# PCIE0_DAT register map
Vendor: Texas Instruments
Peripheral module from a debugger description file (folder am65x).
Registers are 32-bit, read-write, reset 0x0 unless marked. A register's access mark holds for its fields unless they carry their own. Offsets are as the file gives them; lines under a group give offsets from that group; [hi:lo] are bit positions; {n}, {i} and the like mark numbered series; 'fields as' and 'values as' point back to an identical list; <NAME> marks a mode.

## PCIE0_DAT (part 1 of 6)
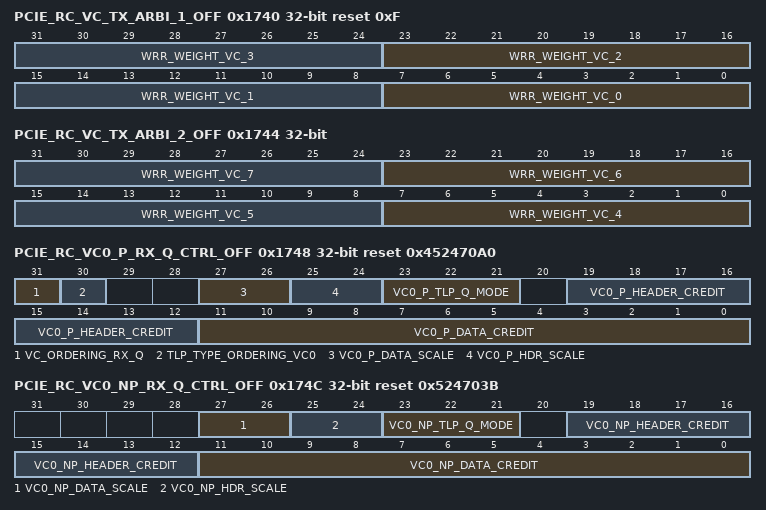
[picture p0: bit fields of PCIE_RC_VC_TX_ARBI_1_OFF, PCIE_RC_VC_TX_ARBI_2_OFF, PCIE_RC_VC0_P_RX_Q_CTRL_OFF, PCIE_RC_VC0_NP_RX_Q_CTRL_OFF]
0x1740 PCIE_RC_VC_TX_ARBI_1_OFF ro reset 0xF — VC Transmit Arbitration Register 1
  [8n+7:8n] WRR_WEIGHT_VC_{n} (n=0..3) — WRR Weight for VC{n} Note: The access attributes of this field are as follows: - Dbi: R
0x1744 PCIE_RC_VC_TX_ARBI_2_OFF ro — VC Transmit Arbitration Register 2
  [8n-25:8n-32] WRR_WEIGHT_VC_{n} (n=4..7) — WRR Weight for VC{n} Note: The access attributes of this field are as follows: - Dbi: R
0x1748 PCIE_RC_VC0_P_RX_Q_CTRL_OFF access per field reset 0x452470A0 — Segmented-Buffer VC0 Posted Receive Queue Control.
  [31] VC_ORDERING_RX_Q rw — VC Ordering for Receive Queues Determines the VC ordering rule for the receive queues, used only in the segmented-buffer configuration: - 1: Strict ordering, higher numbered VCs have higher priority - 0: Round robin Note: This register field is sticky
  [30] TLP_TYPE_ORDERING_VC0 rw — TLP Type Ordering for VC0 Determines the TLP type ordering rule for VC0 receive queues, used only in the segmented-buffer configuration: - 1: PCIe ordering rules [recommended] - 0: Strict ordering: posted, completion, then non-posted Note: This register field is sticky
  [27:26] VC0_P_DATA_SCALE rw — VC0 Scale Posted Data Credites Note: This register field is sticky
  [25:24] VC0_P_HDR_SCALE rw — VC0 Scale Posted Header Credites Note: This register field is sticky
  [23:21] VC0_P_TLP_Q_MODE rw — Reserved Note: This register field is sticky
  [19:12] VC0_P_HEADER_CREDIT ro — VC0 Posted Header Credits The number of initial posted header credits for VC0, used only in the segmented-buffer configuration Note: The access attributes of this field are as follows: - Dbi: R [sticky] Note: This register field is sticky
  [11:0] VC0_P_DATA_CREDIT ro — VC0 Posted Data Credits The number of initial posted data credits for VC0, used only in the segmented-buffer configuration Note: The access attributes of this field are as follows: - Dbi: R [sticky] Note: This register field is sticky
0x174C PCIE_RC_VC0_NP_RX_Q_CTRL_OFF access per field reset 0x524703B — Segmented-Buffer VC0 Non-Posted Receive Queue Control.
  [27:26] VC0_NP_DATA_SCALE rw — VC0 Scale Non-Posted Data Credites Note: This register field is sticky
  [25:24] VC0_NP_HDR_SCALE rw — VC0 Scale Non-Posted Header Credites Note: This register field is sticky
  [23:21] VC0_NP_TLP_Q_MODE rw — Reserved Note: This register field is sticky
  [19:12] VC0_NP_HEADER_CREDIT ro — VC0 Non-Posted Header Credits The number of initial non-posted header credits for VC0, used only in the segmented-buffer configuration Note: The access attributes of this field are as follows: - Dbi: R [sticky] Note: This register field is sticky
  [11:0] VC0_NP_DATA_CREDIT ro — VC0 Non-Posted Data Credits The number of initial non-posted data credits for VC0, used only in the segmented-buffer configuration Note: The access attributes of this field are as follows: - Dbi: R [sticky] Note: This register field is sticky
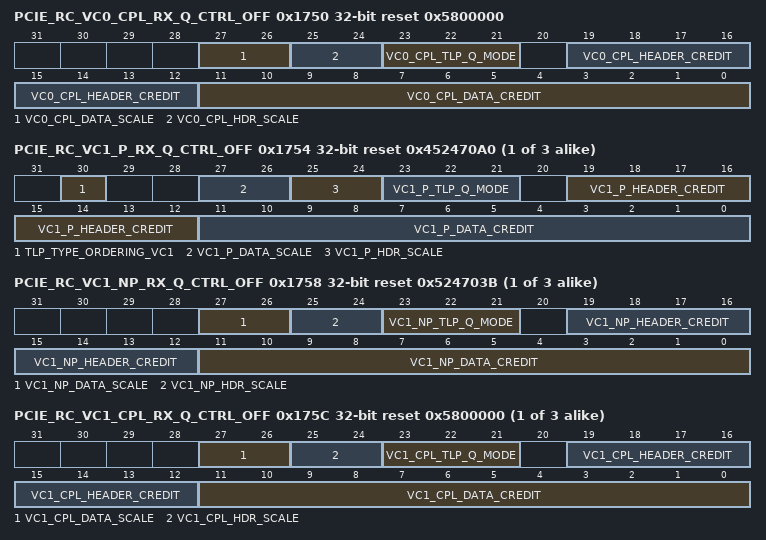
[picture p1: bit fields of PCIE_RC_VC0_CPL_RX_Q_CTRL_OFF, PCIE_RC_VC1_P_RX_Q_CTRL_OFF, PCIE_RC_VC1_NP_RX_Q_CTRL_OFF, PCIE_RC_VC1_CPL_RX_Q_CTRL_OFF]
0x1750 PCIE_RC_VC0_CPL_RX_Q_CTRL_OFF access per field reset 0x5800000 — Segmented-Buffer VC0 Completion Receive Queue Control.
  [27:26] VC0_CPL_DATA_SCALE rw — VC0 Scale CPL Data Credites Note: This register field is sticky
  [25:24] VC0_CPL_HDR_SCALE rw — VC0 Scale CPL Header Credites Note: This register field is sticky
  [23:21] VC0_CPL_TLP_Q_MODE rw — Reserved Note: This register field is sticky
  [19:12] VC0_CPL_HEADER_CREDIT ro — VC0 Completion Header Credits The number of initial Completion header credits for VC0, used only in the segmented-buffer configuration Note: The access attributes of this field are as follows: - Dbi: R [sticky] Note: This register field is sticky
  [11:0] VC0_CPL_DATA_CREDIT ro — VC0 Completion Data Credits The number of initial Completion data credits for VC0, used only in the segmented-buffer configuration Note: The access attributes of this field are as follows: - Dbi: R [sticky] Note: This register field is sticky
{0x1748+0xC*i} PCIE_RC_VC{i}_P_RX_Q_CTRL_OFF access per field reset 0x452470A0 (i=1..3) — Segmented-Buffer VC#i Posted Receive Queue Control.
  [30] TLP_TYPE_ORDERING_VC{i} rw — TLP Type Ordering for VC#i Determines the TLP type ordering rule for VC#i receive queues, used only in the segmented-buffer configuration: - 1: PCIe ordering rules [recommended] - 0: Strict ordering: posted, completion, then non-posted Note: This register field is sticky
  [27:26] VC{i}_P_DATA_SCALE rw — VC{i} Scale Posted Data Credites Note: This register field is sticky
  [25:24] VC{i}_P_HDR_SCALE rw — VC{i} Scale Posted Header Credites Note: This register field is sticky
  [23:21] VC{i}_P_TLP_Q_MODE rw — Reserved Note: This register field is sticky
  [19:12] VC{i}_P_HEADER_CREDIT ro — VC{i} Posted Header Credits The number of initial posted header credits for VC#i, used only in the segmented-buffer configuration Note: The access attributes of this field are as follows: - Dbi: R [sticky] Note: This register field is sticky
  [11:0] VC{i}_P_DATA_CREDIT ro — VC{i} Posted Data Credits The number of initial posted data credits for VC#i, used only in the segmented-buffer configuration Note: The access attributes of this field are as follows: - Dbi: R [sticky] Note: This register field is sticky
{0x174C+0xC*i} PCIE_RC_VC{i}_NP_RX_Q_CTRL_OFF access per field reset 0x524703B (i=1..3) — Segmented-Buffer VC#i Non-Posted Receive Queue Control.
  [27:26] VC{i}_NP_DATA_SCALE rw — VC{i} Scale Non-Posted Data Credites Note: This register field is sticky
  [25:24] VC{i}_NP_HDR_SCALE rw — VC{i} Scale Non-Posted Header Credites Note: This register field is sticky
  [23:21] VC{i}_NP_TLP_Q_MODE rw — Reserved Note: This register field is sticky
  [19:12] VC{i}_NP_HEADER_CREDIT ro — VC#i Non-Posted Header Credits The number of initial non-posted header credits for VC#i, used only in the segmented-buffer configuration Note: The access attributes of this field are as follows: - Dbi: R [sticky] Note: This register field is sticky
  [11:0] VC{i}_NP_DATA_CREDIT ro — VC#i Non-Posted Data Credits The number of initial non-posted data credits for VC#i, used only in the segmented-buffer configuration Note: The access attributes of this field are as follows: - Dbi: R [sticky] Note: This register field is sticky
{0x1750+0xC*i} PCIE_RC_VC{i}_CPL_RX_Q_CTRL_OFF access per field reset 0x5800000 (i=1..3) — Segmented-Buffer VC#i Completion Receive Queue Control.
  [27:26] VC{i}_CPL_DATA_SCALE rw — VC{i} Scale CPL Data Credites Note: This register field is sticky
  [25:24] VC{i}_CPL_HDR_SCALE rw — VC{i} Scale CPL Header Credites Note: This register field is sticky
  [23:21] VC{i}_CPL_TLP_Q_MODE rw — Reserved Note: This register field is sticky
  [19:12] VC{i}_CPL_HEADER_CREDIT ro — VC#i Completion Header Credits The number of initial Completion header credits for VC#i, used only in the segmented-buffer configuration Note: The access attributes of this field are as follows: - Dbi: R [sticky] Note: This register field is sticky
  [11:0] VC{i}_CPL_DATA_CREDIT ro — VC#i Completion Data Credits The number of initial Completion data credits for VC#i, used only in the segmented-buffer configuration Note: The access attributes of this field are as follows: - Dbi: R [sticky] Note: This register field is sticky
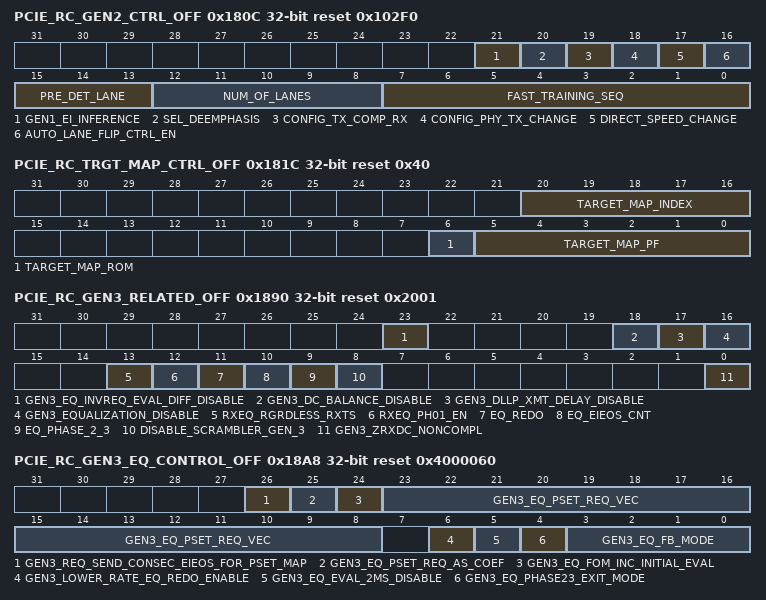
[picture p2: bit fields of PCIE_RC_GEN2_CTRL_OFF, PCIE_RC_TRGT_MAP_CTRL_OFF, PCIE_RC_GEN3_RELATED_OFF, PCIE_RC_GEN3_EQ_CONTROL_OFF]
0x180C PCIE_RC_GEN2_CTRL_OFF access per field reset 0x102F0 — Link Width and Speed Change Control Register.
  [21] GEN1_EI_INFERENCE rw — Electrical Idle Inference Mode at Gen1 Rate Programmable mode to determine inferred electrical idle [EI] in RecoverySpeed or LoopbackActive [as slave] state at Gen1 speed by looking for a '1' value on RxElecIdle instead of looking for a '0' on RxValid If the PHY fails to deassert the RxValid signal in RecoverySpeed or LoopbackActive [because of corrupted EIOS for example], then EI cannot be inferred successfully in the controller by just detecting the condition RxValid= 0 - 0: Use RxElecIdle signal to infer Electrical Idle - 1: Use RxValid signal to infer Electrical Idle Note: This register field is sticky
  [20] SEL_DEEMPHASIS rw — Used to set the de-emphasis level for upstream ports This bit selects the level of de-emphasis the link operates at - 0: -6 dB - 1: -35 dB This field is reserved [fixed to '0'] for M-PCIe Note: The access attributes of this field are as follows: - Dbi: R/W [sticky] Note: This register field is sticky
  [19] CONFIG_TX_COMP_RX rw — Config Tx Compliance Receive Bit When set to 1, signals LTSSM to transmit TS ordered sets with the compliance receive bit assert [equal to '1'] This field is reserved [fixed to '0'] for M-PCIe Note: The access attributes of this field are as follows: - Dbi: R/W [sticky] Note: This register field is sticky
  [18] CONFIG_PHY_TX_CHANGE rw — Config PHY Tx Swing Controls the PHY transmitter voltage swing level The controller drives the mac_phy_txswing output from this register bit field - 0: Full Swing - 1: Low Swing This field is reserved [fixed to '0'] for M-PCIe Note: The access attributes of this field are as follows: - Dbi: R/W [sticky] Note: This register field is sticky
  [17] DIRECT_SPEED_CHANGE rw — Directed Speed Change Writing '1' to this field instructs the LTSSM to initiate a speed change to Gen2 or Gen3 after the link is initialized at Gen1 speed When the speed change occurs, the controller will clear the contents of this field and a read to this field by your software will return a '0' To manually initiate the speed change: - Write to PCIE_RC_LINK_CONTROL2_LINK_STATUS2_REG PCIE_CAP_TARGET_LINK_SPEED in the local device - Deassert this field - Assert this field If you set the default of this field using the DEFAULT_GEN2_SPEED_CHANGE configuration parameter to '1', then the speed change is initiated automatically after link up, and the controller clears the contents of this field If you want to prevent this automatic speed change, then write a lower speed value to the Target Link Speed field of the Link Control 2 register [LINK_CONTROL2_LINK_STATUS2_OFF PCIE_CAP_TARGET_LINK_SPEED] through the DBI before link up This field is reserved [fixed to '0'] for M-PCIe Note: The access attributes of this field are as follows: - Dbi: R/W
  [16] AUTO_LANE_FLIP_CTRL_EN rw — Enable Auto flipping of the lanes You must set the CX_AUTO_LANE_FLIP_CTRL_EN configuration parameter to include the hardware for this feature in the controller This field is reserved [fixed to '0'] for M-PCIe Note: The access attributes of this field are as follows: - Dbi: R/W [sticky] Note: This register field is sticky
  [15:13] PRE_DET_LANE rw — Predetermined Lane for Auto Flip This field defines which physical lane is connected to logical Lane0 by the flip operation performed in Detect Allowed values are: - 3'b 000: Connect logical Lane0 to physical lane 0 or CX_NL-1 or CX_NL/ 2-1 or CX_NL/ 4-1 or CX_NL/ 8-1, depending on which lane is detected - 3'b 001: Connect logical Lane0 to physical lane 1 - 3'b 010: Connect logical Lane0 to physical lane 3 - 3'b 011: Connect logical Lane0 to physical lane 7 - 3'b 100: Connect logical Lane0 to physical lane 15 This field is used to restrict the receiver detect procedure to a particular lane when the default detect and polling procedure performed on all lanes cannot be successful A notable example of when it is useful to program this field to a value different from the default, is when a lane is asymmetrically broken, that is, it is detected in Detect LTSSM state but it cannot exit Electrical Idle in Polling LTSSM state Note: This field is reserved [fixed to '0'] for M-PCIe Note: The access attributes of this field are as follows: - Dbi: R/W [sticky] Note: This register field is sticky
  [12:8] NUM_OF_LANES rw — Predetermined Number of Lanes Defines the number of lanes which are connected and not bad Used to limit the effective link width to ignore 'broken' or 'unused' lanes that detect a receiver Indicates the number of lanes to check for exit from Electrical Idle in PollingActive and L2Idle It is possible that the LTSSM might detect a receiver on a bad or broken lane during the Detect Substate However, it is also possible that such a lane might also fail to exit Electrical Idle and therefore prevent a valid link from being configured This value is referred to as the 'Predetermined Number of Lanes' in section 42621 of the PCI Express Base 30 Specification, revision 10 Encoding is as follows: - 0x 01: 1 lane - 0x 02: 2 lanes - 0x 03: 3 lanes - When you have unused lanes in your system, then you must change the value in this register to reflect the number of lanes You must also change the value in the 'Link Mode Enable' field of PCIE_RC_PORT_LINK_CTRL_OFF The value in this register is normally the same as the encoded value in PCIE_RC_PORT_LINK_CTRL_OFF If you find that one of your used lanes is bad then you must reduce the value in this register This field is reserved [fixed to '0'] for M-PCIe Note: The access attributes of this field are as follows: - Dbi: R/W [sticky] Note: This register field is sticky
  [7:0] FAST_TRAINING_SEQ rw — Sets the Number of Fast Training Sequences [N_FTS] that the controller advertises as its N_FTS during Gen2 or Gen3 link training This value is used to inform the link partner about the PHY's ability to recover synchronization after a low power state Do not set N_FTS to zero doing so can cause the LTSSM to go into the recovery state when exiting from L0s This field is reserved [fixed to '0'] for M-PCIe Note: The access attributes of this field are as follows: - Dbi: R/W [sticky] Note: This register field is sticky
0x1810 PCIE_RC_PHY_STATUS_OFF ro — PHY Status Register. Memory mapped register from phy_cfg_status GPIO input pins.
  [31:0] PHY_STATUS — PHY Status Data received directly from the phy_cfg_status bus These is a GPIO register reflecting the values on the static phy_cfg_status input signals The usage is left completely to the user and does not in any way influence controller functionality You can use it for any static sideband status signalling requirements that you have for your PHY This field is reserved [fixed to '0'] for M-PCIe Note: This register field is sticky
0x1814 PCIE_RC_PHY_CONTROL_OFF — PHY Control Register. Memory mapped register to cfg_phy_control GPIO output pins.
  [31:0] PHY_CONTROL — PHY Control Data sent directly to the cfg_phy_control bus These is a GPIO register driving the values on the static cfg_phy_control output signals The usage is left completely to the user and does not in any way influence controller functionality You can use it for any static sideband control signalling requirements that you have for your PHY This field is reserved [fixed to '0'] for M-PCIe Note: This register field is sticky
0x181C PCIE_RC_TRGT_MAP_CTRL_OFF access per field reset 0x40 — Programmable Target Map Control Register.
  [20:16] TARGET_MAP_INDEX rw — The number of the PF Function on which the Target Values are set This register does not respect the Byte Enable setting any write will affect all register bits
  [6] TARGET_MAP_ROM rw — Target Value for the ROM page of the PF Function selected by the index number This register does not respect the Byte Enable setting any write will affect all register bits
  [5:0] TARGET_MAP_PF rw — Target Values for each BAR on the PF Function selected by the index number This register does not respect the Byte Enable setting any write will affect all register bits
0x1820 PCIE_RC_MSI_CTRL_ADDR_OFF — Integrated MSI Reception Module (iMRM) Address Register.
  [31:0] MSI_CTRL_ADDR — Integrated MSI Reception Module Address System specified address for MSI memory write transaction termination Within the AXI Bridge, every received Memory Write request is examined to see if it targets the MSI Address that has been specified in this register and also to see if it satisfies the definition of an MSI interrupt request When these conditions are satisfied the Memory Write request is marked as an MSI request Note: This register field is sticky
0x1824 PCIE_RC_MSI_CTRL_UPPER_ADDR_OFF — Integrated MSI Reception Module Upper Address Register.
  [31:0] MSI_CTRL_UPPER_ADDR — Integrated MSI Reception Module Upper Address System specified upper address for MSI memory write transaction termination Allows functions to support a 64-bit MSI address Note: This register field is sticky
{0x1828+0xC*i} PCIE_RC_MSI_CTRL_INT_{i}_EN_OFF (i=0..7) — Integrated MSI Reception Module Interrupt#i Enable Register.
  [31:0] MSI_CTRL_INT_{i}_EN — MSI Interrupt#i Enable Specifies which interrupts are enabled When an MSI is received from a disabled interrupt, no status bit gets set in MSI controller interrupt status register Each bit corresponds to a single MSI Interrupt Vector Note: This register field is sticky
{0x182C+0xC*i} PCIE_RC_MSI_CTRL_INT_{i}_MASK_OFF (i=0..7) — Integrated MSI Reception Module Interrupt#i Mask Register.
  [31:0] MSI_CTRL_INT_{i}_MASK — MSI Interrupt#i Mask Allows enabled interrupts to be masked When an MSI is received for a masked interrupt, the corresponding status bit gets set in the interrupt status register but the msi_ctrl_int output is not set HIGH Each bit corresponds to a single MSI Interrupt Vector Note: This register field is sticky
{0x1830+0xC*i} PCIE_RC_MSI_CTRL_INT_{i}_STATUS_OFF access not given (i=0..7) — Integrated MSI Reception Module Interrupt#i Status Register.
  [31:0] MSI_CTRL_INT_{i}_STATUS — MSI Interrupt#i Status When an MSI is detected for EP#i, one bit in this register is set The decoding of the data payload of the MSI Memory Write request determines which bit gets set A status is bit is cleared by writing a 1 to the bit Each bit corresponds to a single MSI Interrupt Vector (access RW1C)
0x1888 PCIE_RC_MSI_GPIO_IO_OFF — Integrated MSI Reception Module General Purpose IO Register.
  [31:0] MSI_GPIO_REG — MSI GPIO Register The contents of this register drives the top-level GPIO msi_ctrl_io[31:0] Note: This register field is sticky
0x188C PCIE_RC_CLOCK_GATING_CTRL_OFF access per field reset 0x1 — RADM clock gating enable control register. Using this register you can disable the RADM clock gating feature. The DWC_pcie_clk_rst.v modules uses the en_radm_clk_g output to gate core_clk and create the radm_clk_g clock input. The controller de-asserts the en_radm_clk_g output when there is no Rx traffic, Rx queues and pre/post-queue pipelines are empty, RADM completion LUT is empty, and there are no FLR actions pending. You must set the RADM_CLK_GATING_EN field to enable this functionality; otherwise the en_radm_clk_g output will always be set to '1'.
  [0] RADM_CLK_GATING_EN rw — Enable Radm clock gating feature - 0: Disable - 1: Enable[default]
0x1890 PCIE_RC_GEN3_RELATED_OFF access per field reset 0x2001 — Gen3 Control Register. There is no Gen3-specific N_FTS field. The N_FTS field in the 'Link Width and Speed Change Control Register' is used for both Gen2 and Gen3 speed modes. There is no Gen3-specific 'Directed Speed Change' field. The 'Directed Speed Change' field in the 'Link Width and Speed Change Control Register' is used to change to Gen2 or Gen3 speed. A speed change to Gen3 occurs if (1) the 'Directed Speed Change' field is set to '1' and (2) the 'Target Link Speed' field in the Link Control 2 Register is set to Gen3. Gen3 support is advertised by both sides of the link during link training. M-PCIe doesn't have Conventional PCIe Gen3 feature. The registers of this section do not exist.
  [23] GEN3_EQ_INVREQ_EVAL_DIFF_DISABLE rw — Eq InvalidRequest and RxEqEval Different Time Assertion Disable Disable the assertion of Eq InvalidRequest and RxEqEval at different time Note: When CX_GEN4_SPEED, this register is shared for Gen3 and Gen4 data rate Note: This register field is sticky
  [18] GEN3_DC_BALANCE_DISABLE rw — DC Balance Disable Disable DC Balance feature Note: When CX_GEN4_SPEED, this register is shared for Gen3 and Gen4 data rate Note: This register field is sticky
  [17] GEN3_DLLP_XMT_DELAY_DISABLE rw — DLLP Transmission Delay Disable Disable delay transmission of DLLPs before equalization Note: When CX_GEN4_SPEED, this register is shared for Gen3 and Gen4 data rate Note: This register field is sticky
  [16] GEN3_EQUALIZATION_DISABLE rw — Equalization Disable Disable equalization feature Note: When CX_GEN4_SPEED, this register is shared for Gen3 and Gen4 data rate Note: This register field is sticky
  [13] RXEQ_RGRDLESS_RXTS rw — When set to '1', the controller as Gen3 EQ master asserts RxEqEval to instruct the PHY to do Rx adaptation and evaluation after a 500ns timeout from a new preset request - 0: mac_phy_rxeqeval asserts after 1us and 2 TS1 received from remote partner - 1: mac_phy_rxeqeval asserts after 500ns regardless of TS's received or not Note: When CX_GEN4_SPEED, this register is shadow register for Gen3 and Gen4 data rate If RATE_SHADOW_SEL==00b, this register is for Gen3 data rate If RATE_SHADOW_SEL==01b, this register is for Gen4 data rate Note: The access attributes of this field are as follows: - Dbi: see description Note: This register field is sticky
  [12] RXEQ_PH01_EN rw — Rx Equalization Phase 0/Phase 1 Hold Enable When this bit is set the upstream port holds phase 0 [the downstream port holds phase 1] for 10ms Holding phase 0 or phase 1 can be used to allow sufficient time for Rx Equalization to be performed by the PHY This bit is used during Virtex-7 Gen3 equalization The programmable bits [RXEQ_PH01_EN, EQ_PHASE_2_3] can be used to obtain the following variations of the equalization procedure: - 00: Tx equalization only in phase 2/ 3 - 01: No Tx equalization, no Rx equalization - 10: Tx equalization in phase 2/3, Rx equalization in phase 0/ 1 - 11: No Tx equalization, Rx equalization in phase 0/1 Note: When CX_GEN4_SPEED, this register is shadow register for Gen3 and Gen4 data rate If RATE_SHADOW_SEL==00b, this register is for Gen3 data rate If RATE_SHADOW_SEL==01b, this register is for Gen4 data rate Note: The access attributes of this field are as follows: - Dbi: see description Note: This register field is sticky
  [11] EQ_REDO rw — Equalization Redo Disable Disable autonomous mechanism for requesting to redo the equalization process Note: When CX_GEN4_SPEED, this register is shared for Gen3 and Gen4 data rate Note: This register field is sticky
  [10] EQ_EIEOS_CNT rw — Equalization EIEOS Count Reset Disable Disable requesting reset of EIEOS count during equalization Note: When CX_GEN4_SPEED, this register is shared for Gen3 and Gen4 data rate Note: This register field is sticky
  [9] EQ_PHASE_2_3 rw — Equalization Phase 2 and Phase 3 Disable This applies to downstream ports only Note: When CX_GEN4_SPEED, this register is shadow register for Gen3 and Gen4 data rate If RATE_SHADOW_SEL==00b, this register is for Gen3 data rate If RATE_SHADOW_SEL==01b, this register is for Gen4 data rate Note: The access attributes of this field are as follows: - Dbi: see description Note: This register field is sticky
  [8] DISABLE_SCRAMBLER_GEN_3 rw — Disable Scrambler for Gen3 and Gen4 Data Rate The Gen3 and Gen4 scrambler/descrambler within the controller needs to be disabled when the scrambling function is implemented outside of the controller [for example within the PHY] Note: When CX_GEN4_SPEED, this register is shared for Gen3 and Gen4 data rate Note: This register field is sticky
  [0] GEN3_ZRXDC_NONCOMPL rw — Gen3 Receiver Impedance ZRX-DC Not Compliant Receivers that operate at 80 GT/s with an impedance other than the range defined by the ZRX-DC parameter for 25 GT/s [40-60 Ohms] must meet additional behavior requirements in the following LTSSM states: Polling, Rx_L0s, L1, L2, and Disabled - 0: The receiver complies with the ZRX-DC parameter for 25 GT/s when operating at 8 GT/s or higher - 1: The receiver does not comply with the ZRX-DC parameter for 25 GT/s when operating at 8 GT/s or higher Note: When CX_GEN4_SPEED, this register is shared for Gen3 and Gen4 data rates Note: This register field is sticky
0x18A8 PCIE_RC_GEN3_EQ_CONTROL_OFF access per field reset 0x4000060 — Gen3 EQ Control Register. This register controls equalization for Phase2 in an upstream port (USP), or Phase3 in a downstream port (DSP). M-PCIe doesn't have Conventional PCIe Gen3 feature. The registers of this section do not exist.
  [26] GEN3_REQ_SEND_CONSEC_EIEOS_FOR_PSET_MAP rw — Request controller to send back-to-back EIEOS in RecoveryRcvrLock state until presets to coefficients mapping is complete - 0: Do not request - 1: request Note: Gen3 and Gen4 share the same register bit and have the same feature Note: This register field is sticky
  [25] GEN3_EQ_PSET_REQ_AS_COEF rw — GEN3_EQ_PSET_REQ_AS_COEF is an internally reserved field Do not use Note: This register field is sticky
  [24] GEN3_EQ_FOM_INC_INITIAL_EVAL rw — Include Initial FOM Include or not the FOM feedback from the initial preset evaluation performed in the EQ Master, when finding the highest FOM among all preset evaluations - 0: Do not include - 1: Include Note: When CX_GEN4_SPEED, this register is shadow register for Gen3 and Gen4 data rate If RATE_SHADOW_SEL==00b, this register is for Gen3 data rate If RATE_SHADOW_SEL==01b, this register is for Gen4 data rate Note: This register field is sticky
  [23:8] GEN3_EQ_PSET_REQ_VEC rw — Preset Request Vector Requesting of Presets during the initial part of the EQ Master Phase Encoding scheme is as follows: Bit [15:0] =0x 0: No preset is requested and evaluated in EQ Master Phase Bit [i] = 1: 'Preset=i' is requested and evaluated in EQ Master Phase - 0000000000000000: No preset be requested and evaluated in EQ Master Phase - 000000xxxxxxxxx 1: Preset 0 is requested and evaluated in EQ Master Phase - 000000xxxxxxxx1x: Preset 1 is requested and evaluated in EQ Master Phase - 000000xxxxxxx1xx: Preset 2 is requested and evaluated in EQ Master Phase - 000000xxxxxx1xxx: Preset 3 is requested and evaluated in EQ Master Phase - 000000xxxxx1xxxx: Preset 4 is requested and evaluated in EQ Master Phase - 000000xxxx1xxxxx: Preset 5 is requested and evaluated in EQ Master Phase - 000000xxx1xxxxxx: Preset 6 is requested and evaluated in EQ Master Phase - 000000xx1xxxxxxx: Preset 7 is requested and evaluated in EQ Master Phase - 000000x1xxxxxxxx: Preset 8 is requested and evaluated in EQ Master Phase - 00000x1xxxxxxxxx: Preset 9 is requested and evaluated in EQ Master Phase - 000001xxxxxxxxxx: Preset 10 is requested and evaluated in EQ Master Phase - All other encodings: Reserved Note: You must ensure 24 ms timeout does not occur in presets requests in EQ master phase, ie, you must set a proper value to the GEN3_EQ_PSET_REQ_VEC register so that the EQ tunning for Figure of Merit in the EQ master phase completes before 24 ms timeout Note: When CX_GEN4_SPEED, this register is shadow register for Gen3 and Gen4 data rate If RATE_SHADOW_SEL==00b, this register is for Gen3 data rate If RATE_SHADOW_SEL==01b, this register is for Gen4 data rate Note: This register field is sticky
  [6] GEN3_LOWER_RATE_EQ_REDO_ENABLE rw — Support EQ redo and lower rate change: - 0: not support - 1: support Note: Gen3 and Gen4 share the same register bit and have the same feature Note: This register field is sticky
  [5] GEN3_EQ_EVAL_2MS_DISABLE rw — Phase2_3 2 ms Timeout Disable Determine behavior in Phase2 for USP [Phase3 if DSP] when the PHY does not respond within 2ms to the assertion of RxEqEval: - 0: abort the current evaluation, stop any attempt to modify the remote transmitter settings, Phase2 is terminated by the 24ms timeout - 1: ignore the 2ms timeout and continue as normal This is used to support PHYs that require more than 2ms to respond to the assertion of RxEqEval Note: When CX_GEN4_SPEED, this register is shadow register for Gen3 and Gen4 data rate If RATE_SHADOW_SEL==00b, this register is for Gen3 data rate If RATE_SHADOW_SEL==01b, this register is for Gen4 data rate Note: This register field is sticky
  [4] GEN3_EQ_PHASE23_EXIT_MODE rw — Behavior After 24 ms Timeout [when optimal settings are not found] For a USP: Determine next LTSSM state from Phase2 after 24ms Timeout - 0: RecoverySpeed - 1: RecoveryEqualizationPhase3 When optimal settings are not found then: - Equalization Phase 2 Successful status bit is not set in the 'Link Status Register 2' when GEN3_EQ_PHASE23_EXIT_MODE = 0 - Equalization Phase 2 Successful status bit is set in the 'Link Status Register 2' when GEN3_EQ_PHASE23_EXIT_MODE = 1 - Equalization Phase 2 Complete status bit is set in the 'Link Status Register 2' For a DSP: Determine next LTSSM state from Phase3 after 24ms Timeout - 0: RecoverySpeed - 1: RecoveryEqualizationRcvrLock When optimal settings are not found then: - Equalization Phase 3 Successful status bit is not set in the 'Link Status Register 2' when GEN3_EQ_PHASE23_EXIT_MODE = 0 - Equalization Phase 3 Successful status bit is set in the 'Link Status Register 2' when GEN3_EQ_PHASE23_EXIT_MODE = 1 - Equalization Phase 3 Complete status bit is set in the 'Link Status Register 2' Note: GEN3_EQ_PHASE23_EXIT_MODE = 1 affects Direction Change feed back mode EQ requests for Figure Of Merit mode complete before 24 ms timeout Please see GEN3_EQ_PSET_REQ_VEC Register for more Note: When CX_GEN4_SPEED, this register is shadow register for Gen3 and Gen4 data rate If RATE_SHADOW_SEL==00b, this register is for Gen3 data rate If RATE_SHADOW_SEL==01b, this register is for Gen4 data rate Note: This register field is sticky
  [3:0] GEN3_EQ_FB_MODE rw — Feedback Mode - 0000b: Direction Change - 0001b: Figure Of Merit - 0010b: Reserved - : Reserved - 1111b: Reserved Note: When CX_GEN4_SPEED, this register is a shadow register for Gen3 and Gen4 data rate If RATE_SHADOW_SEL==00b, this register is for Gen3 data rate If RATE_SHADOW_SEL==01b, this register is for Gen4 data rate Note: This register field is sticky
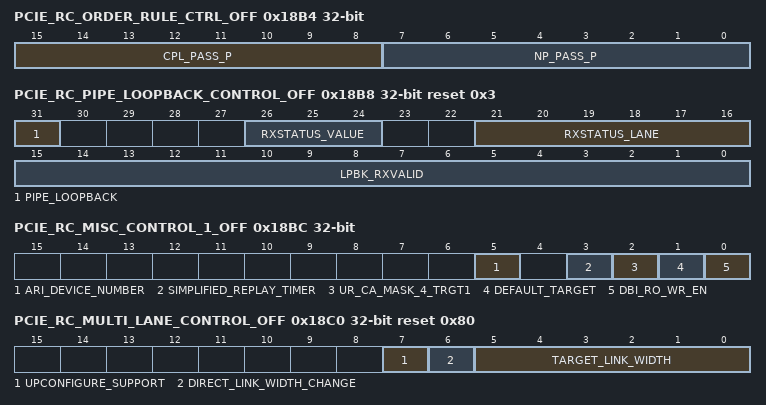
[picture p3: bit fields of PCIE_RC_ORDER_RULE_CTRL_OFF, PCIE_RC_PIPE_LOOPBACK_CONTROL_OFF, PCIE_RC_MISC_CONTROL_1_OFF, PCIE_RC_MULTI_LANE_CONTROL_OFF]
0x18B4 PCIE_RC_ORDER_RULE_CTRL_OFF access per field — Order Rule Control Register.
  [15:8] CPL_PASS_P rw — Completion Passing Posted Ordering Rule Control Determines if CPL can pass halted P queue - 0: CPL can not pass P [recommended] - 1: CPL can pass P
  [7:0] NP_PASS_P rw — Non-Posted Passing Posted Ordering Rule Control Determines if NP can pass halted P queue - 0 : NP can not pass P [recommended] - 1 : NP can pass P
0x18B8 PCIE_RC_PIPE_LOOPBACK_CONTROL_OFF access per field reset 0x3 — PIPE Loopback Control Register.
  [31] PIPE_LOOPBACK rw — PIPE Loopback Enable Indicates RMMI Loopback if M-PCIe Note: This register field is sticky
  [26:24] RXSTATUS_VALUE rw — RXSTATUS_VALUE is an internally reserved field Do not use
  [21:16] RXSTATUS_LANE rw — RXSTATUS_LANE is an internally reserved field Do not use Note: This register field is sticky
  [15:0] LPBK_RXVALID rw — LPBK_RXVALID is an internally reserved field Do not use Note: This register field is sticky
0x18BC PCIE_RC_MISC_CONTROL_1_OFF access per field — DBI Read-Only Write Enable Register.
  [5] ARI_DEVICE_NUMBER rw — When ARI is enabled, enables use of the device ID Note: This register field is sticky
  [3] SIMPLIFIED_REPLAY_TIMER rw — Enables Simplified Replay Timer [Gen4] Simplified Replay Timer Values are: - A value from 24,000 to 31,000 Symbol Times when Extended Synch is 0b - A value from 80,000 to 100,000 Symbol Times when Extended Synch is 1b Must not be changed while link is in use Note: This register field is sticky
  [2] UR_CA_MASK_4_TRGT1 rw — This field only applies to request TLPs [with UR filtering status] that you have chosen to forward to the application [when you set DEFAULT_TARGET in this register] - When you set this field to '1', the core suppresses error logging, Error Message generation, and CPL generation [for non-posted requests] - You should set this if you have set the Default Target port logic register to '1' Default is CX_MASK_UR_CA_4_TRGT1 configuration parameter Note: This register field is sticky
  [1] DEFAULT_TARGET rw — Default target a received IO or MEM request with UR/CA/CRS is sent to by the controller - 0: The controller drops all incoming I/O or MEM requests [after corresponding error reporting] A completion with UR status will be generated for non-posted requests - 1: The controller forwards all incoming I/O or MEM requests with UR/CA/CRS status to your application Default value is DEFAULT_TARGET configuration parameter Note: This register field is sticky
  [0] DBI_RO_WR_EN rw — Write to RO Registers Using DBI When you set this field to '1', then some RO and HwInit bits are writable from the local application through the DBI Note: This register field is sticky
0x18C0 PCIE_RC_MULTI_LANE_CONTROL_OFF access per field reset 0x80 — UpConfigure Multi-lane Control Register. Used when upsizing or downsizing the link width through Configuration state without bringing the link down.
  [7] UPCONFIGURE_SUPPORT rw — Upconfigure Support The controller sends this value as the Link Upconfigure Capability in TS2 Ordered Sets in ConfigurationComplete state This field is reserved [fixed to '0'] for M-PCIe Note: This register field is sticky
  [6] DIRECT_LINK_WIDTH_CHANGE rw — Directed Link Width Change The controller always moves to Configuration state through Recovery state when this bit is set to '1' - If the upconfigure_capable variable is '1' and the PCIE_CAP_HW_AUTO_WIDTH_DISABLE bit in
  [5:0] TARGET_LINK_WIDTH rw — Target Link Width Values correspond to: - 6'b 000000: Core does not start upconfigure or autonomous width downsizing in the Configuration state - 6'b 000001: x 1 - 6'b 000010: x 2 - 6'b 000100: x 4 - 6'b 001000: x 8 - 6'b 010000: x 16 - 6'b 100000: x32 This field is reserved [fixed to '0'] for M-PCIe
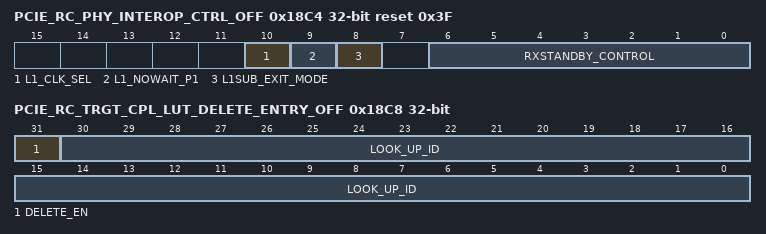
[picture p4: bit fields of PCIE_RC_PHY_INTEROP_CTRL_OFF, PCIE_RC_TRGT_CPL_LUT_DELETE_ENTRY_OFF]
0x18C4 PCIE_RC_PHY_INTEROP_CTRL_OFF access per field reset 0x3F — PHY Interoperability Control Register. This register is reserved for internal use. You should not write to this register and change the default.
  [10] L1_CLK_SEL rw — L1 Clock control bit - 1: Controller does not request aux_clk switch and core_clk gating in L 1 - 0: Controller requests aux_clk switch and core_clk gating in L1 Note: This register field is sticky
  [9] L1_NOWAIT_P1 rw — L1 entry control bit - 1: Core does not wait for PHY to acknowledge transition to P1 before entering L 1 - 0: Core waits for the PHY to acknowledge transition to P1 before entering L1 Note: The access attributes of this field are as follows: - Dbi: R/W [sticky] Note: This register field is sticky
  [8] L1SUB_EXIT_MODE rw — L1 Exit Control Using phy_mac_pclkack_n - 1: Core exits L1 without waiting for the PHY to assert phy_mac_pclkack_n - 0: Core waits for the PHY to assert phy_mac_pclkack_n before exiting L1 Note: This register field is sticky
  [6:0] RXSTANDBY_CONTROL rw — Rxstandby Control Bits 05 determine if the controller asserts the RxStandby signal [mac_phy_rxstandby] in the indicated condition Bit 6 enables the controller to perform the RxStandby/RxStandbyStatus handshake - [0]: Rx EIOS and subsequent T TX-IDLE-MIN - [1]: Rate Change - [2]: Inactive lane for upconfigure/downconfigure - [3]: PowerDown=P1orP 2 - [4]: RxL0sIdle - [5]: EI Infer in L 0 - [6]: Execute RxStandby/RxStandbyStatus Handshake This field is reserved [fixed to '0'] for M-PCIe Note: This register field is sticky
0x18C8 PCIE_RC_TRGT_CPL_LUT_DELETE_ENTRY_OFF access not given — TRGT_CPL_LUT Delete Entry Control register. Using this register you can delete one entry in the target completion LUT. You should only use this register when you know that your application will never send the completion because of an FLR or any other reason. Note:: The target completion LUT (and associated target completion timeout event) is watching for completions (from your application on XALI0/1/2 or AXI master read channel) corresponding to previously received non-posted requests from the PCIe wire.
  [31] DELETE_EN — This is a one-shot bit A '1' write to this bit triggers the deletion of the target completion LUT entry that is specified in the LOOK_UP_ID field This is a self-clearing register field Reading from this register field always returns a '0' (access RW1C)
  [30:0] LOOK_UP_ID rw — This number selects one entry to delete of the TRGT_CPL_LUT
0x18CC PCIE_RC_LINK_FLUSH_CONTROL_OFF access per field reset 0xFF000001 — Link Reset Request Flush Control Register.
  [0] AUTO_FLUSH_EN rw — Enables automatic flushing of pending requests before sending the reset request to the application logic to reset the PCIe controller and the AXI Bridge The flushing process is initiated if any of the following events occur: - Hot reset request A downstream port [DSP] can 'hot reset' an upstream port [USP] by sending two consecutive TS1 ordered sets with the hot reset bit asserted - Warm [Soft] reset request Generated when exiting from D3 to D0 and cfg_pm_no_soft_rst= 0 - Link down reset request A high to low transition on smlh_req_rst_not indicates the link has gone down and the controller is requesting a reset If you disable automatic flushing, your application is responsible for resetting the PCIe controller and the AXI Bridge Note: This register field is sticky
